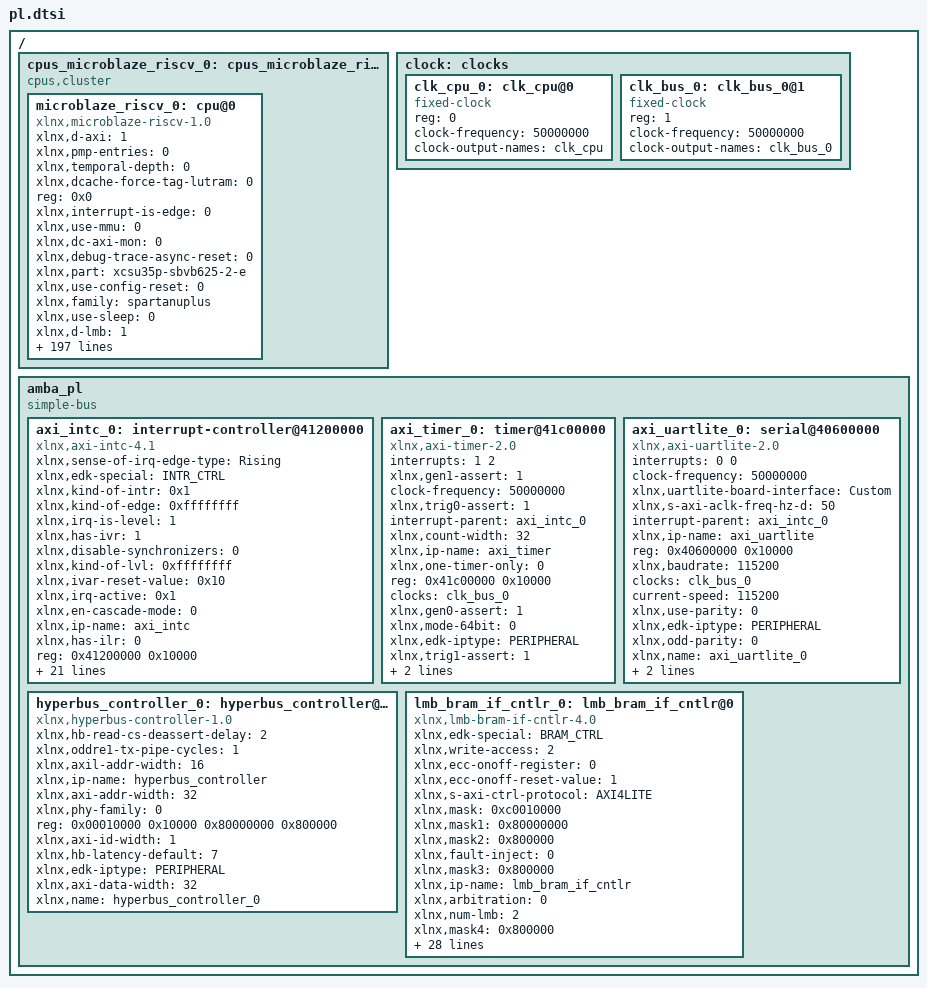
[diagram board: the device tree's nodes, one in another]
/ {
	cpus_microblaze_riscv_0: cpus_microblaze_riscv@0 {
		#cpu-mask-cells = <1>;
		compatible = "cpus,cluster";
		#address-cells = <1>;
		#size-cells = <0>;
		microblaze_riscv_0: cpu@0 {
			xlnx,d-axi = <1>;
			xlnx,pmp-entries = <0>;
			xlnx,temporal-depth = <0>;
			xlnx,dcache-force-tag-lutram = <0>;
			reg = <0x0>;
			xlnx,interrupt-is-edge = <0>;
			xlnx,use-mmu = <0>;
			xlnx,dc-axi-mon = <0>;
			xlnx,debug-trace-async-reset = <0>;
			xlnx,part = "xcsu35p-sbvb625-2-e";
			xlnx,use-config-reset = <0>;
			xlnx,family = "spartanuplus";
			xlnx,use-sleep = <0>;
			xlnx,d-lmb = <1>;
			xlnx,enable-discrete-ports = <0>;
			xlnx,debug-interface = <0>;
			xlnx,use-ext-brk = <0>;
			xlnx,debug-enabled = <1>;
			xlnx,daddr-size = <32>;
			xlnx,use-extended-fsl-instr = <0>;
			xlnx,branch-target-cache-size = <0>;
			bus-handle = <&amba_pl>;
			xlnx,pmp-addr0 = <0x0>;
			xlnx,pmp-addr1 = <0x0>;
			xlnx,pmp-addr2 = <0x0>;
			xlnx,pmp-addr3 = <0x0>;
			xlnx,pmp-addr4 = <0x0>;
			xlnx,edk-special = "microblaze_riscv";
			xlnx,use-dcache = <1>;
			xlnx,pmp-addr5 = <0x0>;
			xlnx,use-muldiv = <2>;
			xlnx,pmp-addr6 = <0x0>;
			xlnx,use-axi-dp-ext-addr = <0>;
			xlnx,pmp-addr7 = <0x0>;
			xlnx,pmp-addr8 = <0x0>;
			xlnx,pmp-addr9 = <0x0>;
			xlnx,i-axi = <0>;
			xlnx,icache-streams = <0>;
			xlnx,i-lmb-has-prot = <0>;
			xlnx,num-sync-ff-dbg-clk = <1>;
			xlnx,icache-byte-size = <4096>;
			xlnx,pmp-addr10 = <0x0>;
			d-cache-size = <4096>;
			xlnx,pmp-addr11 = <0x0>;
			xlnx,pmp-addr12 = <0x0>;
			xlnx,pmp-addr13 = <0x0>;
			xlnx,pmp-addr14 = <0x0>;
			xlnx,pmp-addr15 = <0x0>;
			xlnx,avoid-primitives = <0>;
			xlnx,pmp-addr16 = <0x0>;
			xlnx,pmp-addr17 = <0x0>;
			xlnx,pmp-addr18 = <0x0>;
			xlnx,pdaddr-size = <32>;
			xlnx,pmp-addr19 = <0x0>;
			xlnx,pmp-addr20 = <0x0>;
			xlnx,pmp-addr21 = <0x0>;
			xlnx,i-lmb = <1>;
			xlnx,pmp-addr22 = <0x0>;
			xlnx,lmb-data-size = <32>;
			xlnx,lockstep-select = <0>;
			xlnx,pmp-addr23 = <0x0>;
			timebase-frequency = <50000000>;
			xlnx,pmp-addr24 = <0x0>;
			xlnx,dcache-data-width = <0>;
			xlnx,icache-force-tag-lutram = <0>;
			xlnx,pmp-addr25 = <0x0>;
			xlnx,pmp-addr26 = <0x0>;
			xlnx,use-branch-target-cache = <0>;
			xlnx,pmp-addr27 = <0x0>;
			xlnx,number-of-pc-brk = <1>;
			xlnx,pmp-addr28 = <0x0>;
			xlnx,imprecise-exceptions = <0>;
			xlnx,pmp-addr29 = <0x0>;
			xlnx,pmp-addr30 = <0x0>;
			xlnx,pmp-addr31 = <0x0>;
			xlnx,pmp-addr32 = <0x0>;
			model = "microblaze_riscv,1.0";
			xlnx,pmp-addr33 = <0x0>;
			xlnx,pmp-addr34 = <0x0>;
			xlnx,pmp-addr35 = <0x0>;
			xlnx,pmp-addr36 = <0x0>;
			d-cache-highaddr = <0x807fffff>;
			xlnx,optimization = <1>;
			xlnx,pmp-addr37 = <0x0>;
			xlnx,pmp-addr38 = <0x0>;
			xlnx,pmp-addr39 = <0x0>;
			xlnx,pmp-addr40 = <0x0>;
			xlnx,pmp-addr41 = <0x0>;
			xlnx,d-lmb-mon = <0>;
			xlnx,pmp-addr42 = <0x0>;
			xlnx,pmp-addr43 = <0x0>;
			xlnx,pmp-addr44 = <0x0>;
			xlnx,pmp-addr45 = <0x0>;
			xlnx,pmp-addr46 = <0x0>;
			xlnx,pmp-addr47 = <0x0>;
			xlnx,pmp-addr48 = <0x0>;
			xlnx,fault-tolerant = <0>;
			xlnx,pmp-addr49 = <0x0>;
			xlnx,pmp-addr50 = <0x0>;
			xlnx,pmp-addr51 = <0x0>;
			xlnx,pmp-enhancements = <0>;
			d-cache-line-size = <16>;
			xlnx,mmu-privileged-instr = <0>;
			xlnx,pmp-addr52 = <0x0>;
			clock-frequency = <50000000>;
			xlnx,pmp-addr53 = <0x0>;
			xlnx,pmp-addr54 = <0x0>;
			xlnx,pmp-addr55 = <0x0>;
			xlnx,i-lmb-protocol = <0>;
			xlnx,pmp-addr56 = <0x0>;
			xlnx,pmp-addr57 = <0x0>;
			xlnx,dp-axi-mon = <0>;
			xlnx,pmp-addr58 = <0x0>;
			xlnx,pmp-addr59 = <0x0>;
			xlnx,pmp-addr60 = <0x0>;
			xlnx,pmp-addr61 = <0x0>;
			xlnx,pmp-addr62 = <0x0>;
			xlnx,pmp-addr63 = <0x0>;
			xlnx,debug-external-trace = <0>;
			xlnx,addr-size = <32>;
			xlnx,debug-num-progbuf = <2>;
			xlnx,debug-event-counters = <0>;
			xlnx,edk-iptype = "PROCESSOR";
			xlnx,debug-latency-counters = <0>;
			xlnx,interconnect = <2>;
			xlnx,edge-is-positive = <1>;
			xlnx,use-icache = <1>;
			xlnx,async-wakeup = <3>;
			xlnx,s-axi = <0>;
			xlnx,use-ext-nm-brk = <0>;
			xlnx,ic-axi-mon = <0>;
			xlnx,archid = <0x1>;
			xlnx,num-sync-ff-clk-irq = <1>;
			xlnx,freq = <50000000>;
			xlnx,lockstep-master = <0>;
			xlnx,pmp-cfg0 = <0x0>;
			xlnx,pmp-cfg1 = <0x0>;
			xlnx,iaddr-size = <32>;
			xlnx,interrupt-mon = <0>;
			xlnx,pmp-cfg2 = <0x0>;
			xlnx,number-of-wr-addr-brk = <0>;
			xlnx,pmp-cfg3 = <0x0>;
			xlnx,pmp-cfg4 = <0x0>;
			xlnx,use-interrupt = <1>;
			xlnx,pmp-cfg5 = <0x0>;
			xlnx,async-interrupt = <1>;
			xlnx,pc-width = <16>;
			xlnx,pmp-cfg6 = <0x0>;
			xlnx,icache-victims = <0>;
			xlnx,pmp-cfg7 = <0x0>;
			xlnx,pmp-cfg8 = <0x0>;
			xlnx,pmp-cfg9 = <0x0>;
			xlnx,use-bitman-a = <1>;
			xlnx,use-bitman-b = <1>;
			xlnx,use-bitman-c = <1>;
			xlnx,i-lmb-mon = <0>;
			xlnx,dcache-byte-size = <4096>;
			xlnx,data-size = <32>;
			compatible = "xlnx,microblaze-riscv-1.0" , "xlnx,microblaze_riscv";
			xlnx,pmp-debug-inhibit = <0x0>;
			xlnx,use-sstc = <1>;
			xlnx,fsl-exception = <0>;
			xlnx,dcache-use-writeback = <0>;
			device_type = "cpu";
			xlnx,impid = <0x1>;
			xlnx,use-bitman-s = <1>;
			xlnx,base-vectors = <0x0>;
			xlnx,icache-line-len = <4>;
			xlnx,d-lmb-has-prot = <0>;
			xlnx,use-barrel = <1>;
			xlnx,misaligned-exceptions = <1>;
			xlnx,piaddr-size = <32>;
			xlnx,use-bitman = <15>;
			xlnx,dcache-line-len = <4>;
			xlnx,num-sync-ff-clk = <2>;
			xlnx,memory-ip-list = "lmb_bram_if_cntlr_0_memory" , "lmb_bram_if_cntlr_0_memory";
			xlnx,number-of-rd-addr-brk = <0>;
			xlnx,use-counters = <1>;
			xlnx,lockstep-slave = <0>;
			interrupt-handle = <&axi_intc_0>;
			xlnx,pmp-cfg10 = <0x0>;
			xlnx,pmp-cfg11 = <0x0>;
			xlnx,debug-profile-size = <0>;
			xlnx,pmp-cfg12 = <0x0>;
			xlnx,pmp-cfg13 = <0x0>;
			xlnx,pmp-cfg14 = <0x0>;
			xlnx,pmp-cfg15 = <0x0>;
			xlnx,debug-counter-width = <64>;
			xlnx,icache-data-width = <0>;
			xlnx,ip-name = "microblaze_riscv";
			xlnx,ip-axi-mon = <0>;
			xlnx,d-lmb-protocol = <0>;
			xlnx,trace = <0>;
			xlnx,ill-instr-exception = <1>;
			xlnx,debug-trace-size = <0>;
			xlnx,pmp-granularity = <2>;
			xlnx,num-sync-ff-dbg-trace-clk = <2>;
			xlnx,ecc-use-ce-exception = <0>;
			xlnx,num-sync-ff-clk-debug = <2>;
			xlnx,use-atomic = <1>;
			xlnx,g-template-list = <1>;
			xlnx,trap-enhancement = <0>;
			xlnx,hartid = <0x0>;
			xlnx,use-fpu = <0>;
			xlnx,use-non-secure = <0>;
			d-cache-baseaddr = <0x80000000>;
			xlnx,use-compression = <1>;
			xlnx,instr-size = <32>;
			xlnx,fsl-links = <0>;
			xlnx,dcache-victims = <0>;
			xlnx,pmp-read-only = <0x0>;
		};
	};
	clock: clocks {
		#address-cells = <1>;
		#size-cells = <0>;
		clk_cpu_0: clk_cpu@0 {
			compatible = "fixed-clock";
			reg = <0>;
			clock-frequency = <50000000>;
			clock-output-names = "clk_cpu";
			#clock-cells = <0>;
		};
		clk_bus_0: clk_bus_0@1 {
			compatible = "fixed-clock";
			reg = <1>;
			clock-frequency = <50000000>;
			clock-output-names = "clk_bus_0";
			#clock-cells = <0>;
		};
	};
	amba_pl: amba_pl {
		ranges;
		compatible = "simple-bus";
		#address-cells = <1>;
		#size-cells = <1>;
		axi_intc_0: interrupt-controller@41200000 {
			#interrupt-cells = <2>;
			xlnx,sense-of-irq-edge-type = "Rising";
			xlnx,edk-special = "INTR_CTRL";
			xlnx,kind-of-intr = <0x1>;
			xlnx,kind-of-edge = <0xffffffff>;
			xlnx,irq-is-level = <1>;
			xlnx,has-ivr = <1>;
			compatible = "xlnx,axi-intc-4.1" , "xlnx,xps-intc-1.00.a";
			xlnx,disable-synchronizers = <0>;
			xlnx,kind-of-lvl = <0xffffffff>;
			xlnx,ivar-reset-value = <0x10>;
			xlnx,irq-active = <0x1>;
			xlnx,en-cascade-mode = <0>;
			xlnx,ip-name = "axi_intc";
			xlnx,has-ilr = <0>;
			reg = <0x41200000 0x10000>;
			xlnx,addr-width = <0x20>;
			xlnx,s-axi-aclk-freq-mhz = <50>;
			xlnx,num-sw-intr = <0>;
			xlnx,irq-connection = <0>;
			xlnx,num-intr-inputs = <0x2>;
			xlnx,has-sie = <1>;
			xlnx,enable-async = <0>;
			xlnx,has-cie = <1>;
			xlnx,num-sync-ff = <2>;
			xlnx,edk-iptype = "PERIPHERAL";
			xlnx,mb-clk-not-connected = <1>;
			xlnx,has-ipr = <1>;
			xlnx,sense-of-irq-level-type = "Active_High";
			xlnx,cascade-master = <0>;
			xlnx,processor-clk-freq-mhz = <100>;
			status = "okay";
			xlnx,is-fast = <0x0>;
			xlnx,has-fast = <0>;
			xlnx,ivar-rst-val = <0x10>;
			interrupt-controller;
			xlnx,async-intr = <0xfffffffc>;
			xlnx,name = "axi_intc_0";
		};
		axi_timer_0: timer@41c00000 {
			interrupts = < 1 2 >;
			compatible = "xlnx,axi-timer-2.0" , "xlnx,xps-timer-1.00.a";
			xlnx,gen1-assert = <1>;
			clock-frequency = <50000000>;
			xlnx,trig0-assert = <1>;
			interrupt-parent = <&axi_intc_0>;
			xlnx,count-width = <32>;
			xlnx,ip-name = "axi_timer";
			xlnx,one-timer-only = <0>;
			reg = <0x41c00000 0x10000>;
			clocks = <&clk_bus_0>;
			xlnx,gen0-assert = <1>;
			xlnx,mode-64bit = <0>;
			xlnx,edk-iptype = "PERIPHERAL";
			status = "okay";
			xlnx,trig1-assert = <1>;
			xlnx,enable-timer2 = <1>;
			interrupt-names = "interrupt";
			xlnx,name = "axi_timer_0";
		};
		axi_uartlite_0: serial@40600000 {
			interrupts = < 0 0 >;
			compatible = "xlnx,axi-uartlite-2.0" , "xlnx,xps-uartlite-1.00.a";
			clock-frequency = <50000000>;
			xlnx,uartlite-board-interface = "Custom";
			xlnx,s-axi-aclk-freq-hz-d = <50>;
			interrupt-parent = <&axi_intc_0>;
			xlnx,ip-name = "axi_uartlite";
			reg = <0x40600000 0x10000>;
			xlnx,baudrate = <115200>;
			clocks = <&clk_bus_0>;
			current-speed = <115200>;
			xlnx,use-parity = <0>;
			xlnx,edk-iptype = "PERIPHERAL";
			xlnx,odd-parity = <0>;
			status = "okay";
			interrupt-names = "interrupt";
			xlnx,name = "axi_uartlite_0";
			xlnx,data-bits = <8>;
			xlnx,parity = "No_Parity";
		};
		hyperbus_controller_0: hyperbus_controller@10000 {
			compatible = "xlnx,hyperbus-controller-1.0";
			xlnx,hb-read-cs-deassert-delay = <2>;
			xlnx,oddre1-tx-pipe-cycles = <1>;
			xlnx,axil-addr-width = <16>;
			xlnx,ip-name = "hyperbus_controller";
			xlnx,axi-addr-width = <32>;
			xlnx,phy-family = <0>;
			reg = <0x00010000 0x10000 0x80000000 0x800000>;
			xlnx,axi-id-width = <1>;
			xlnx,hb-latency-default = <7>;
			xlnx,edk-iptype = "PERIPHERAL";
			status = "okay";
			xlnx,axi-data-width = <32>;
			xlnx,name = "hyperbus_controller_0";
		};
		lmb_bram_if_cntlr_0: lmb_bram_if_cntlr@0 {
			xlnx,edk-special = "BRAM_CTRL";
			xlnx,write-access = <2>;
			compatible = "xlnx,lmb-bram-if-cntlr-4.0" , "xlnx,axi-bram-ctrl";
			xlnx,ecc-onoff-register = <0>;
			xlnx,ecc-onoff-reset-value = <1>;
			xlnx,s-axi-ctrl-protocol = "AXI4LITE";
			xlnx,mask = <0xc0010000>;
			xlnx,mask1 = <0x80000000>;
			xlnx,mask2 = <0x800000>;
			xlnx,fault-inject = <0>;
			xlnx,mask3 = <0x800000>;
			xlnx,ip-name = "lmb_bram_if_cntlr";
			xlnx,arbitration = <0>;
			xlnx,num-lmb = <2>;
			xlnx,mask4 = <0x800000>;
			reg = <0x00000000 0x10000>;
			xlnx,s-axi-ctrl-addr-width = <32>;
			xlnx,mask5 = <0x800000>;
			xlnx,ecc-status-registers = <0>;
			xlnx,prot-cfg = <0xff>;
			xlnx,mask6 = <0x800000>;
			xlnx,lmb-protocol = <0>;
			xlnx,ce-counter-width = <0>;
			xlnx,prot-cfg1 = <0xff>;
			xlnx,mask7 = <0x800000>;
			xlnx,ecc = <0>;
			xlnx,edk-iptype = "PERIPHERAL";
			xlnx,prot-cfg2 = <0xff>;
			xlnx,lmb-dwidth = <32>;
			xlnx,interconnect = <0>;
			xlnx,ce-failing-registers = <0>;
			xlnx,prot-cfg3 = <0xff>;
			xlnx,ue-failing-registers = <0>;
			xlnx,prot-cfg4 = <0xff>;
			xlnx,lmb-has-prot = <0>;
			status = "okay";
			xlnx,data-width = <32>;
			xlnx,prot-cfg5 = <0xff>;
			xlnx,s-axi-ctrl-data-width = <32>;
			xlnx,prot-cfg6 = <0xff>;
			xlnx,bram-awidth = <32>;
			xlnx,prot-cfg7 = <0xff>;
			xlnx,lmb-awidth = <32>;
			xlnx,name = "lmb_bram_if_cntlr_0";
		};
	};
};
